CM_ "IMPORT _vw_meb_common.dbc";

BO_ 190 MEB_HVEM_01: 48 XXX
 SG_ CRC : 0|8@1+ (1,0) [0|255] "" XXX
 SG_ CNT : 8|4@1+ (1,0) [0|15] "" XXX
 SG_ Engine_RPM_Max : 12|14@1+ (2,-9658) [0|15] "RPM" XXX
 SG_ Engine_RPM_Min : 26|14@1+ (2,-10300) [0|63] "RPM" XXX
 SG_ In_Motion_04 : 48|3@1+ (1,0) [0|7] "" XXX
 SG_ In_Motion_03 : 52|1@0+ (1,0) [0|1] "" XXX
 SG_ In_Motion_02 : 54|1@0+ (1,0) [0|1] "" XXX
 SG_ Engine_Power : 56|12@1+ (0.5,-1023) [0|255] "kW" XXX
 SG_ In_Motion : 68|1@1+ (1,0) [0|3] "" XXX
 SG_ Standstill : 71|1@0+ (1,0) [0|1] "" XXX
 SG_ Unknown_04 : 72|10@1+ (1,0) [0|255] "" XXX
 SG_ Voltage : 86|12@1+ (0.24,0) [0|3] "V" XXX
 SG_ Unknown_01 : 100|9@1+ (1,0) [0|7] "" XXX
 SG_ Battery_Voltage : 113|13@1+ (0.065,0) [0|127] "V" XXX
 SG_ Engine_Status : 296|2@1+ (1,0) [0|3] "" XXX
 SG_ Inactive : 300|1@0+ (1,0) [0|1] "" XXX
 SG_ Inactive_02 : 303|1@0+ (1,0) [0|1] "" XXX

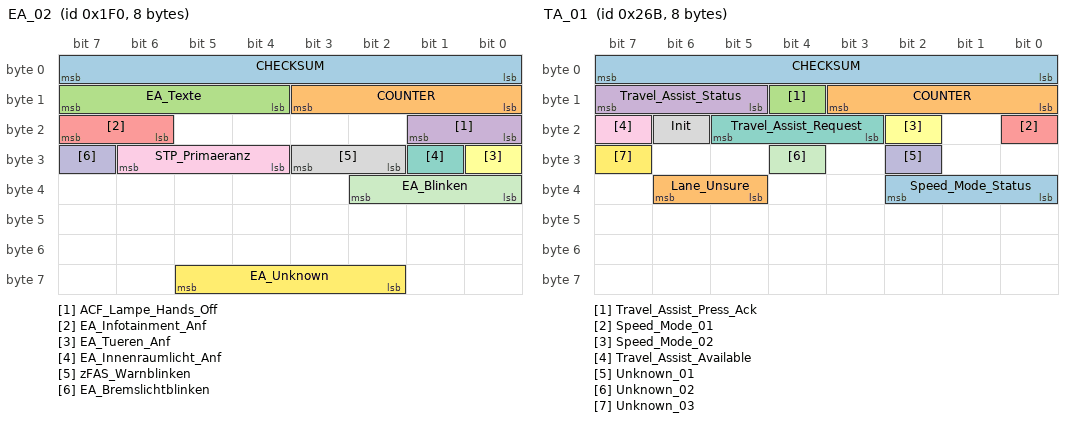
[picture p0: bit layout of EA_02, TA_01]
BO_ 496 EA_02: 8 Gateway
 SG_ CHECKSUM : 0|8@1+ (1,0) [0|255] "" Vector__XXX
 SG_ COUNTER : 8|4@1+ (1,0) [0|15] "" Vector__XXX
 SG_ EA_Texte : 12|4@1+ (1,0) [0|15] "" ZR_High
 SG_ ACF_Lampe_Hands_Off : 16|2@1+ (1,0) [0|3] "" Vector__XXX
 SG_ EA_Infotainment_Anf : 22|2@1+ (1,0) [0|3] "" ZR_High,ZR_LIMU,ZR_MIB_TOP_ab_Gen3,ZR_Standard
 SG_ EA_Tueren_Anf : 24|1@1+ (1,0) [0|1] "" ZR_High
 SG_ EA_Innenraumlicht_Anf : 25|1@1+ (1,0) [0|1] "" ZR_High
 SG_ zFAS_Warnblinken : 26|2@1+ (1,0) [0|3] "" ZR_High
 SG_ STP_Primaeranz : 28|3@1+ (1,0) [0|7] "" Vector__XXX
 SG_ EA_Bremslichtblinken : 31|1@1+ (1,0) [0|1] "" Vector__XXX
 SG_ EA_Blinken : 32|3@1+ (1,0) [0|7] "" Vector__XXX
 SG_ EA_Unknown : 61|4@0+ (1,0) [0|7] "" XXX

BO_ 768 ACC_19: 48 XXX
 SG_ ACC_Tempolimit : 64|5@1+ (1,0) [0|31] "" OTA_FC
 SG_ ACC_Wunschgeschw_Farbe : 69|1@1+ (1,0) [0|1] "" Vector__XXX
 SG_ ACC_Warnung_Verkehrszeichen_1 : 70|1@1+ (1,0) [0|1] "" Vector__XXX
 SG_ ACA_Querfuehrung : 71|2@1+ (1,0) [0|3] "" Vector__XXX
 SG_ ACC_Regelung_AIO : 75|1@1+ (1,0) [0|1] "" ZR_High,ZR_LIMU,ZR_MIB_TOP_ab_Gen3
 SG_ ACC_Wunschgeschw_02 : 76|10@1+ (0.32,0) [0|327.04] "Unit_KiloMeterPerHour" Vector__XXX
 SG_ ACC_Abstandsindex_02 : 86|10@1+ (1,0) [1|1021] "" Vector__XXX
 SG_ ACC_Display_Prio : 96|2@1+ (1,0) [0|3] "" Vector__XXX
 SG_ ACC_rel_Objekt_Zusatzanz : 98|2@1+ (1,0) [0|3] "" Vector__XXX
 SG_ ACC_Gesetzte_Zeitluecke : 101|3@1+ (1,0) [0|7] "" Vector__XXX
 SG_ ACC_Optischer_Fahrerhinweis : 104|1@1+ (1,0) [0|1] "" Vector__XXX
 SG_ ACC_Warnhinweis : 105|1@1+ (1,0) [0|1] "" Vector__XXX
 SG_ ACC_EGO_Fahrzeug : 106|3@1+ (1,0) [0|7] "" Vector__XXX
 SG_ ACC_Relevantes_Objekt_02 : 109|2@1+ (1,0) [0|3] "" OTA_FC,ZR_High,ZR_LIMU,ZR_MIB_TOP_ab_Gen3
 SG_ ACC_Wunschgeschw_erreicht : 112|1@1+ (1,0) [0|1] "" OTA_FC
 SG_ ACC_Anzeige_Zeitluecke : 113|1@1+ (1,0) [0|1] "" Vector__XXX
 SG_ ACC_Texte_Primaeranz_02 : 114|6@1+ (1,0) [0|63] "" Vector__XXX
 SG_ ACC_Texte_Zusatzanz_02 : 120|6@1+ (1,0) [0|63] "" Vector__XXX
 SG_ STA_Primaeranz : 126|2@1+ (1,0) [0|3] "" Vector__XXX
 SG_ ACC_Event_Wunschgeschw : 140|10@1+ (0.32,0) [0|15] "" XXX
 SG_ Heartbeat : 150|9@1+ (1,0) [0|3] "" XXX
 SG_ SET_ME_0XFFFF : 160|16@1+ (1,0) [0|65535] "" XXX
 SG_ ACC_Enabled : 186|1@0+ (1,0) [0|1] "" XXX
 SG_ Zeitluecke_Farbe : 189|1@0+ (1,0) [0|1] "" XXX
 SG_ SET_ME_0X1 : 199|1@0+ (1,0) [0|1] "" XXX
 SG_ ACC_Status_ACC : 208|3@1+ (1,0) [0|7] "" XXX
 SG_ ACC_Akustischer_Fahrerhinweis : 211|2@1+ (1,0) [0|1] "" XXX
 SG_ SET_ME_0X7FFF : 240|16@1+ (1,0) [0|65535] "" XXX
 SG_ Lead_Type_Detected : 265|1@0+ (1,0) [0|1] "" XXX
 SG_ ACC_Standby_Override : 266|1@0+ (1,0) [0|1] "" XXX
 SG_ Street_Color : 267|1@0+ (1,0) [0|1] "" XXX
 SG_ ACC_Limiter_Mode : 268|1@0+ (1,0) [0|1] "" XXX
 SG_ Lead_Brightness : 269|4@1+ (1,0) [0|7] "" XXX
 SG_ SET_ME_0X6A : 273|8@1+ (1,0) [0|7] "" XXX
 SG_ Lead_Type_Left : 281|3@1+ (1,0) [0|7] "" XXX
 SG_ Lead_Type_Right : 284|3@1+ (1,0) [0|7] "" XXX
 SG_ Lead_Type : 287|3@1+ (1,0) [0|3] "" XXX
 SG_ Lead_Distance : 290|10@1+ (0.17,0) [0|150] "Unit_Meter" XXX
 SG_ Lead_Distance_Right : 300|10@1+ (0.17,0) [0|150] "Unit_Meter" XXX
 SG_ Lead_Distance_Left : 310|10@1+ (0.17,0) [0|150] "Unit_Meter" XXX
 SG_ ACC_Events : 332|4@0+ (1,0) [0|3] "Unit_Meter" XXX
 SG_ Zeitluecke_1 : 334|9@1+ (0.135,0) [0|70] "Unit_Meter" XXX
 SG_ Zeitluecke_2 : 344|9@1+ (0.135,0) [0|70] "Unit_Meter" XXX
 SG_ Zeitluecke_3 : 354|9@1+ (0.135,0) [0|70] "Unit_Meter" XXX
 SG_ Zeitluecke_4 : 364|9@1+ (0.135,0) [0|70] "Unit_Meter" XXX
 SG_ Zeitluecke_5 : 374|9@1+ (0.135,0) [0|70] "Unit_Meter" XXX

BO_ 252 ESC_51: 64 XXX
 SG_ CHECKSUM : 0|8@1+ (1,0) [0|255] "" XXX
 SG_ COUNTER : 8|4@1+ (1,0) [0|15] "" XXX
 SG_ NEW_SIGNAL_2 : 14|6@1+ (1,0) [0|3] "" XXX
 SG_ AEB_Breaking_01 : 24|8@1+ (1,0) [0|255] "" XXX
 SG_ AEB_Breaking_02 : 32|8@1+ (1,0) [0|255] "" XXX
 SG_ Accelerator_Higher_Speed : 40|1@0+ (1,0) [0|1] "" XXX
 SG_ Brake_Pressure : 42|9@1+ (0.195,0) [0|100] "Unit_Percent" XXX
 SG_ NEW_SIGNAL_1 : 52|8@1+ (1,0) [0|15] "" XXX
 SG_ HL_Radgeschw : 64|16@1+ (0.0075,0) [0|491.5125] "Unit_KilometerPerHour" XXX
 SG_ HR_Radgeschw : 80|16@1+ (0.0075,0) [0|491.5125] "Unit_KilometerPerHour" XXX
 SG_ VL_Radgeschw : 96|16@1+ (0.0075,0) [0|491.5125] "Unit_KilometerPerHour" XXX
 SG_ VR_Radgeschw : 112|16@1+ (0.0075,0) [0|491.5125] "Unit_KilometerPerHour" XXX
 SG_ NEW_SIGNAL_3 : 128|4@1+ (1,0) [0|15] "" XXX
 SG_ HL_Brake_Pressure : 152|8@1+ (1,0) [0|100] "" XXX
 SG_ HR_Brake_Pressure : 160|8@1+ (1,0) [0|100] "" XXX
 SG_ VL_Brake_Pressure : 168|8@1+ (1,0) [0|100] "" XXX
 SG_ VR_Brake_Pressure : 176|8@1+ (1,0) [0|100] "" XXX
 SG_ Steering_Wheel_CW : 184|8@1+ (1.67,0) [0|255] "" XXX
 SG_ Steering_Wheel_CCW : 192|8@1+ (1.67,0) [0|255] "" XXX
 SG_ ESC_v_Signal : 328|13@1+ (0.052,-107.016) [0|63] "" XXX
 SG_ NEW_SIGNAL_4 : 342|13@1+ (1,0) [0|3] "" XXX

BO_ 267 Motor_51: 48 XXX
 SG_ CHECKSUM : 0|8@1+ (1,0) [0|255] "" XXX
 SG_ COUNTER : 8|4@1+ (1,0) [0|15] "" XXX
 SG_ Accel_Pedal_Pressure : 12|9@1+ (0.4,0) [0|255] "" XXX
 SG_ Accel_Low_Pressed_Support : 21|1@1+ (1,0) [0|7] "" XXX
 SG_ TSK_Status : 88|3@1+ (1,0) [0|7] "" XXX
 SG_ TSK_Limiter_ausgewaehlt : 95|1@1+ (1,0) [0|3] "" XXX

BO_ 333 ACC_18: 32 XXX
 SG_ CHECKSUM : 0|8@1+ (1,0) [0|255] "" XXX
 SG_ COUNTER : 8|4@1+ (1,0) [0|15] "" XXX
 SG_ ACC_limitierte_Anfahrdyn : 12|1@1+ (1,0) [0|1] "" XXX
 SG_ ACC_nachtr_Stopp_Anf : 13|1@1+ (1,0) [0|1] "" XXX
 SG_ ACC_DynErhoehung : 14|1@1+ (1,0) [0|1] "" XXX
 SG_ ACC_Freilaufstrategie_TSK : 15|1@1+ (1,0) [0|1] "" XXX
 SG_ ACC_zul_Regelabw_unten : 16|6@1+ (0.024,0) [0|1.512] "Unit_MeterPerSeconSquar" XXX
 SG_ ACC_StartStopp_Info : 22|2@1+ (1,0) [0|3] "" XXX
 SG_ ACC_Sollbeschleunigung_02 : 24|11@1+ (0.005,-7.22) [-7.22|3.005] "Unit_MeterPerSeconSquar" XXX
 SG_ ACC_zul_Regelabw_oben : 35|5@1+ (0.0625,0) [0|1.9375] "Unit_MeterPerSeconSquar" XXX
 SG_ ACC_neg_Sollbeschl_Grad_02 : 40|8@1+ (0.05,0) [0|12.75] "Unit_MeterPerCubicSecon" XXX
 SG_ ACC_pos_Sollbeschl_Grad_02 : 48|8@1+ (0.05,0) [0|12.75] "Unit_MeterPerCubicSecon" XXX
 SG_ ACC_Anfahren : 56|1@1+ (1,0) [0|1] "" XXX
 SG_ ACC_Anhalten : 57|1@1+ (1,0) [0|1] "" XXX
 SG_ ACC_Typ : 58|2@1+ (1,0) [0|3] "" XXX
 SG_ ACC_Status_ACC : 60|3@1+ (1,0) [0|7] "" XXX
 SG_ ACC_Minimale_Bremsung : 63|1@1+ (1,0) [0|1] "" XXX
 SG_ ACC_Anhalteweg : 64|11@1+ (0.01,0) [0|2046] "" XXX
 SG_ ACC_Anforderung_HMS : 77|3@1+ (1,0) [0|7] "" XXX
 SG_ SET_ME_0XFE : 80|8@1+ (1,0) [0|255] "" XXX
 SG_ ACC_AKTIV_regelt : 90|1@0+ (1,0) [0|1] "" XXX
 SG_ SET_ME_0X1 : 92|1@0+ (1,0) [0|1] "" XXX
 SG_ SET_ME_0x2FE : 98|10@1+ (1,0) [0|63] "" XXX
 SG_ SET_ME_0X9 : 232|4@1+ (1,0) [0|15] "" XXX
 SG_ Speed : 236|12@1+ (0.1,0) [0|15] "" XXX
 SG_ Accel_Boost : 248|6@1+ (1,0) [0|3] "" XXX
 SG_ Reversing : 254|1@0+ (1,0) [0|1] "" XXX

BO_ 619 TA_01: 8 XXX
 SG_ CHECKSUM : 0|8@1+ (1,0) [0|255] "" XXX
 SG_ COUNTER : 8|4@1+ (1,0) [0|15] "" XXX
 SG_ Travel_Assist_Press_Ack : 12|1@1+ (1,0) [0|1] "" XXX
 SG_ Travel_Assist_Status : 13|3@1+ (1,0) [0|3] "" XXX
 SG_ Speed_Mode_01 : 16|1@0+ (1,0) [0|1] "" XXX
 SG_ Speed_Mode_02 : 18|1@0+ (1,0) [0|1] "" XXX
 SG_ Travel_Assist_Request : 19|3@1+ (1,0) [0|7] "" XXX
 SG_ Init : 22|1@0+ (1,0) [0|1] "" XXX
 SG_ Travel_Assist_Available : 23|1@1+ (1,0) [0|1] "" XXX
 SG_ Unknown_01 : 26|1@0+ (1,0) [0|1] "" XXX
 SG_ Unknown_02 : 28|1@0+ (1,0) [0|1] "" XXX
 SG_ Unknown_03 : 31|1@0+ (1,0) [0|1] "" XXX
 SG_ Speed_Mode_Status : 32|3@1+ (1,0) [0|7] "" XXX
 SG_ Lane_Unsure : 37|2@1+ (1,0) [0|3] "" XXX

BO_ 389241616 MEB_Camera_09: 3 XXX

VAL_ 267 TSK_Status 0 "init" 1 "disabled" 2 "enabled" 3 "regulating" 4 "accel_pedal_override" 5 "brake_only" 6 "temp_fault" 7 "perm_fault";
VAL_ 333 ACC_limitierte_Anfahrdyn 0 "keine_Limitierung" 1 "Limitierung_Anfahrdynamik_angefordert";
VAL_ 333 ACC_nachtr_Stopp_Anf 0 "nicht_angefordert" 1 "angefordert";
VAL_ 333 ACC_StartStopp_Info 0 "Motorlauf_langfristig_nicht_notwendig_Stoppfreigabe" 1 "Motoranlauf_nicht_zwingend_notwendig_Stoppverbot_keine_Startanforderung" 2 "Motoranlauf_zwingend_notwendig_Startanforderung" 3 "Systemfehler";
VAL_ 333 ACC_Sollbeschleunigung_02 2046 "Neutralwert" 2047 "Fehler";
VAL_ 333 ACC_Anfahren 0 "keine_Anforderung_Anfahren" 1 "Anforderung_Anfahren";
VAL_ 333 ACC_Anhalten 0 "kein_Anhalten_gewuenscht" 1 "Anhalten_gewuenscht";
VAL_ 333 ACC_Typ 0 "Basis_ACC" 1 "ACC_mit_FollowToStop" 2 "ACC_mit_StopAndGo" 3 "ACC_nicht_codiert";
VAL_ 333 ACC_Status_ACC 0 "ACC_OFF_Hauptschalter_aus" 1 "ACC_INIT" 2 "ACC_STANDBY" 3 "ACC_AKTIV_regelt" 4 "ACC_OVERRIDE" 5 "ACC_Abschaltreaktion" 6 "reversibler_Fehler_im_ACC_System" 7 "irreversibler_Fehler_im_ACC_System";
VAL_ 333 ACC_Minimale_Bremsung 0 "Anforderung_Minimale_Bremsung_nicht_aktiv" 1 "Anforderung_Minimale_Bremsung_aktiv";
VAL_ 333 ACC_Anhalteweg 2046 "Neutralwert" 2047 "Fehler";
VAL_ 333 ACC_Anforderung_HMS 0 "keine_Anforderung" 1 "halten" 2 "parken" 3 "halten_Standby" 4 "anfahren" 5 "Loesen_ueber_Rampe";
VAL_ 333 Accel_Boost 3 "Driving" 0 "Stop" 2 "Driving" 1 "Driving";
VAL_ 619 Travel_Assist_Status 4 "enabled" 0 "disabled" 2 "ready" 3 "pre_ready";
VAL_ 619 Travel_Assist_Request 4 "enable" 3 "disable" 0 "no_request" 1 "error";
VAL_ 619 Travel_Assist_Available 0 "not_available" 1 "available";

VAL_ 190 Engine_Status 1 "Ready" 2 "Online";
VAL_ 496 EA_Texte 0 "keine_Anzeige" 1 "Nothalteassistent_fehlende_Fahreraktivitaet" 2 "Nothalteassistent_aktiv_Fahrzeugfuehrung_uebernehmen" 3 "Nothalteassistent_automatischer_Nothalt_wird_durchgefuehrt" 4 "Nothalteassistent_automatischer_Nothalt_durchgefuehrt" 5 "Nothalteassistent_Verbindung_zum_Notruf_wird_aufgebaut" 6 "Nothalteassistent_deaktiviert" 7 "Nothalteassistent_Eingriff_abgebrochen" 8 "Nothalteassistent_fehlende_Fahreraktivitaet_2" 9 "Sekundenschlaf_erkannt" 10 "LaneAssist_Lenkung_uebernehmen" 11 "ACA_Fahrzeugfuehrung_uebernehmen" 12 "EA_Fahr_Standstreifenwechsel" 14 "Nothalteassistent_nicht_verfuegbar_reversibel" 15 "Nothalteassistent_Stoerung_irreversibel";
VAL_ 496 ACF_Lampe_Hands_Off 0 "keine_Anzeige" 1 "Hands_Off_erkannt";
VAL_ 496 EA_Infotainment_Anf 0 "Init" 1 "Keine_Absenkung" 2 "Absenkung" 3 "Mute";
VAL_ 496 EA_Tueren_Anf 0 "Keine_Anforderung" 1 "Tueren_entriegeln";
VAL_ 496 EA_Innenraumlicht_Anf 0 "Innenraumbeleuchtung_ausschalten" 1 "Innenraumbeleuchtung_einschalten";
VAL_ 496 zFAS_Warnblinken 0 "Aus" 1 "Statisch" 2 "Taster" 3 "Statisch_ohne_WBT";
VAL_ 496 STP_Primaeranz 0 "keine_Anzeige" 1 "Verfuegbar" 2 "Aktiv" 3 "Uebernahme" 4 "Aktiv_Warnung" 5 "Nicht_Verfuegbar";
VAL_ 496 EA_Bremslichtblinken 0 "kein_Blinken" 1 "Anforderung_Bremslichtblinken";
VAL_ 496 EA_Blinken 0 "Kein_Blinken" 1 "Wechselblinken_links" 2 "Wechselblinken_rechts" 3 "Warnblinken" 4 "Warnblinken_Taster";
VAL_ 768 ACC_Tempolimit 0 "keine_Anzeige" 1 "5_zulHoechstgeschw" 2 "7_zulHoechstgeschw" 3 "10_zulHoechstgeschw" 4 "15_zulHoechstgeschw" 5 "20_zulHoechstgeschw" 6 "25_zulHoechstgeschw" 7 "30_zulHoechstgeschw" 8 "35_zulHoechstgeschw" 9 "40_zulHoechstgeschw" 10 "45_zulHoechstgeschw" 11 "50_zulHoechstgeschw" 12 "55_zulHoechstgeschw" 13 "60_zulHoechstgeschw" 14 "65_zulHoechstgeschw" 15 "70_zulHoechstgeschw" 16 "75_zulHoechstgeschw" 17 "80_zulHoechstgeschw" 18 "85_zulHoechstgeschw" 19 "90_zulHoechstgeschw" 20 "95_zulHoechstgeschw" 21 "100_zulHoechstgeschw" 22 "110_zulHoechstgeschw" 23 "120_zulHoechstgeschw" 24 "130_zulHoechstgeschw" 25 "140_zulHoechstgeschw" 26 "150_zulHoechstgeschw" 27 "160_zulHoechstgeschw" 28 "200_zulHoechstgeschw" 30 "250_zulHoechstgeschw" 31 "Ende_zulHoechstgeschw";
VAL_ 768 ACC_Wunschgeschw_Farbe 0 "Grundfarbe" 1 "Farbe_1";
VAL_ 768 ACC_Warnung_Verkehrszeichen_1 0 "keine_Warnung_Initialwert" 1 "Warnung";
VAL_ 768 ACA_Querfuehrung 0 "keine_Anzeige_oder_init" 1 "passiv" 2 "aktiv" 3 "Warnung";
VAL_ 768 ACC_Regelung_AIO 0 "Regelung_Ampel_nicht_aktiv" 1 "Regelung_Ampel_aktiv";
VAL_ 768 ACC_Wunschgeschw_02 1023 "keine_Anzeige";
VAL_ 768 ACC_Abstandsindex_02 0 "Audi (Init), VW (passiv/aktiv_Freifahrt)" 1022 "aus_passiv" 1023 "aktiv_Freifahrt";
VAL_ 768 ACC_Display_Prio 0 "hoechste_Prio" 1 "mittlere_Prio" 2 "geringe_Prio" 3 "keine_Prio";
VAL_ 768 ACC_rel_Objekt_Zusatzanz 0 "keine Anzeige" 1 "Relevantes_Objekt_erkannt" 2 "Relevantes_Objekt_Abstandswarnung";
VAL_ 768 ACC_Gesetzte_Zeitluecke 0 "keine_Anzeige" 1 "Zeitluecke_1" 2 "Zeitluecke_2" 3 "Zeitluecke_3" 4 "Zeitluecke_4" 5 "Zeitluecke_5" 6 "nicht_definiert" 7 "nicht_definiert";
VAL_ 768 ACC_Optischer_Fahrerhinweis 0 "optischer_Fahrerhinweis_AUS" 1 "optischer_Fahrerhinweis_EIN";
VAL_ 768 ACC_Warnhinweis 0 "kein_Warnhinweis" 1 "Warnhinweis";
VAL_ 768 ACC_EGO_Fahrzeug 0 "keine_Anzeige" 1 "aktiv" 2 "Warnung" 3 "aktiv_stop" 4 "passiv";
VAL_ 768 ACC_Relevantes_Objekt_02 0 "keine_Anzeige" 1 "Relevantes_Objekt_erkannt" 2 "Relevantes_Objekt_Warnung" 3 "passiv";
VAL_ 768 ACC_Wunschgeschw_erreicht 0 "Wunschgeschwindigkeit_nicht_erreicht" 1 "Wunschgeschwindigkeit_erreicht";
VAL_ 768 ACC_Anzeige_Zeitluecke 0 "Anzeige_Zeitluecke_nicht_angefordert" 1 "Anzeige_Zeitluecke_angefordert";
VAL_ 768 ACC_Texte_Primaeranz_02 0 "keine Anzeige" 1 "VDA_ACC_Symbol_YYY_kmh_mph" 2 "Kurven_Symbol_YYY_kmh_mph" 3 "Tempolimit_Symbol_YYY_kmh_mph" 4 "ACC_anfahrbereit" 5 "eingestellte_Zeitluecke" 6 "Tuer offen !" 7 "Stehendes Objekt voraus" 8 "o  o  o" 9 "ACC aus" 10 "ACC startet" 11 "ACC Sensor Sicht !" 12 "ACC nicht verfuegbar" 13 "ACC Fehler" 14 "ESP Eingriff" 15 "ESP PASSIV !" 16 "Parkbremse !" 17 "Geschwindigkeitsgrenze" 18 "Waehlhebelposition !" 19 "Fahrer Gurtschloss offen !" 20 "Schalthebelposition !" 21 "Drehzahl !" 22 "HDC aktiv" 23 "Kupplung betaetigt" 24 "Gang einlegen !" 25 "Bremse ueberhitzt !" 26 "Steigung_Gefaelle_zu_gross" 27 "ABSTAND" 28 "Rechtsueberholen_verhindert" 29 "Linksueberholen_verhindert" 30 "Kreuzungs_Symbol" 31 "Kreisverkehr_Symbol" 32 "Gefaelle_Symbol" 33 "Tempolimit_Kurvenassistent_ein" 34 "Kurvenassistent_ein" 35 "Tempolimitassistent_ein" 36 "Achtung_Geschwindigkeitsueberschreitung" 37 "Tempolimit_und_Kurvenassistent_nicht_verfuegbar" 38 "Tempolimit_nicht_verfuegbar" 39 "Kurvenassistent_nicht_verfuegbar" 40 "Autobahnausfahrt_Symbol" 41 "Stauende_Symbol" 42 "Engstelle_Symbol" 43 "STP_verfuegbar" 44 "Ampel_vertikal" 45 "Ampel_horizontal" 46 "STA_verfuegbar";
VAL_ 768 ACC_Texte_Zusatzanz_02 0 "keine_Anzeige" 1 "ACC_AUS" 2 "Standby" 3 "UEBERTRETEN" 4 "ABSTAND" 5 "DISTANZ_1" 6 "DISTANZ_2" 7 "DISTANZ_3" 8 "DISTANZ_4" 9 "DISTANZ_5" 10 "DISTANZ_1__dyn" 11 "DISTANZ_2__dyn" 12 "DISTANZ_3__dyn" 13 "DISTANZ_4__dyn" 14 "DISTANZ_5__dyn" 15 "DISTANZ_1__comf" 16 "DISTANZ_2__comf" 17 "DISTANZ_3__comf" 18 "DISTANZ_4__comf" 19 "DISTANZ_5__comf" 20 "DISTANZ_1__efficiency" 21 "DISTANZ_2__efficiency" 22 "DISTANZ_3__efficiency" 23 "DISTANZ_4__efficiency" 24 "DISTANZ_5__efficiency" 25 "DISTANZ_1__Stau" 26 "DISTANZ_2__Stau" 27 "DISTANZ_3__Stau" 28 "DISTANZ_4__Stau" 29 "DISTANZ_5__Stau" 30 "ACHTUNG" 31 "Abstandsanzeige" 32 "Abstandsanzeige_Warnung_aktiviert" 33 "STA_verfuegbar" 34 "Engstelle" 35 "RUV_aktiv_Rechtsverkehr" 36 "RUV_aktiv_Linksverkehr" 37 "STP_Verfuegbar" 38 "AW_Warnschwelle_1" 39 "AW_Warnschwelle_2" 40 "AW_Warnschwelle_3" 41 "AW_Warnung_1" 42 "AW_Warnung_2" 43 "AW_Warnung_3";
VAL_ 768 STA_Primaeranz 0 "keine_Anzeige" 1 "STA_standby" 2 "STA_aktiv" 3 "STA_Warnung";
VAL_ 768 ACC_Event_Wunschgeschw 1023 "None";
VAL_ 768 Heartbeat 1 "ACC_Init_Low" 420 "ACC_Init_High" 221 "ACC_Available_Low" 360 "ACC_Available_High";
VAL_ 768 ACC_Status_ACC 0 "ACC_OFF_Hauptschalter_aus" 1 "ACC_INIT" 2 "ACC_STANDBY" 3 "ACC_AKTIV_regelt" 4 "ACC_OVERRIDE" 5 "ACC_Abschaltreaktion" 6 "reversibler_Fehler_im_ACC_System" 7 "irreversibler_Fehler_im_ACC_System";
VAL_ 768 Lead_Type_Detected 1 "Lead_Detected" 0 "No_Lead_Detected";
VAL_ 768 Lead_Type 5 "Bicycle" 3 "Car" 0 "None" 2 "Truck" 4 "Motorcycle";
VAL_ 768 ACC_Events 3 "Starting_Available" 0 "None" 5 "Speed_Limit_Detected" 9 "Crossing" 4 "Speed_Limit_Ahead" 10 "Roundabout" 6 "Curve";
VAL_ 768 Zeitluecke_1 0 "keine Anzeige";
VAL_ 768 Zeitluecke_2 0 "keine Anzeige" 32 "Minimum";
VAL_ 768 Zeitluecke_3 0 "keine Anzeige";
VAL_ 768 Zeitluecke_4 0 "keine Anzeige" 40 "Minimum";
VAL_ 768 Zeitluecke_5 0 "keine Anzeige";
